# LPC18xx register map
File version: 0.23
CPU: CM3 r0p0, little endian, no MPU, no FPU, 3 interrupt priority bits
Registers are 32-bit, read-write, reset 0x0 unless marked. A register's access mark holds for its fields unless they carry their own. Offsets are from the block's base; [hi:lo] are bit positions; {n}, {i} and the like mark numbered series.

## TIMER0 — Timer0/1/2/3
Base 0x40084000
Same registers: TIMER1 0x40085000, TIMER2 0x400C3000, TIMER3 0x400C4000
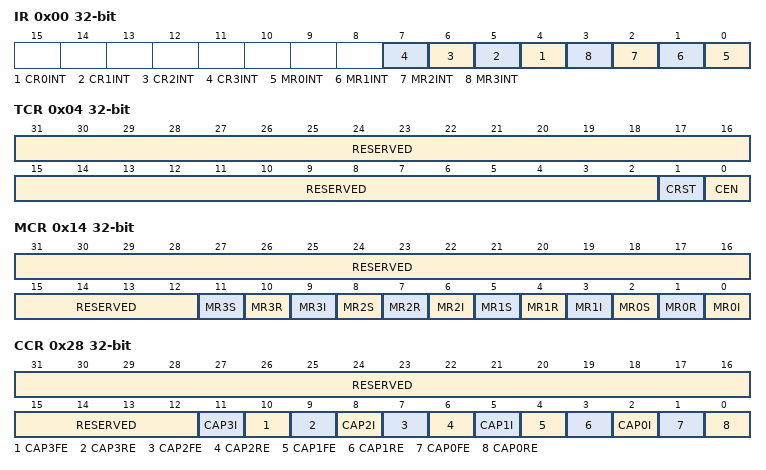
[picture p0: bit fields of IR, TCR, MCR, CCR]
0x00 IR — Interrupt Register. The IR can be written to clear interrupts. The IR can be read to identify which of eight possible interrupt sources are pending.
  [n+4] CR{n}INT (n=0..3) — Interrupt flag for capture channel {n} event.
  [n] MR{n}INT (n=0..3) — Interrupt flag for match channel {n}.
0x04 TCR — Timer Control Register. The TCR is used to control the Timer Counter functions. The Timer Counter can be disabled or reset through the TCR.
  [31:2] RESERVED — Reserved, user software should not write ones to reserved bits. The value read from a reserved bit is not defined.
  [1] CRST — When one, the Timer Counter and the Prescale Counter are synchronously reset on the next positive edge of PCLK. The counters remain reset until TCR[1] is returned to zero.
  [0] CEN — When one, the Timer Counter and Prescale Counter are enabled for counting. When zero, the counters are disabled.
0x08 TC — Timer Counter. The 32 bit TC is incremented every PR+1 cycles of PCLK. The TC is controlled through the TCR.
  [31:0] TC — Timer counter value.
0x0C PR — Prescale Register. When the Prescale Counter (PC) is equal to this value, the next clock increments the TC and clears the PC.
  [31:0] PM — Prescale counter maximum value.
0x10 PC — Prescale Counter. The 32 bit PC is a counter which is incremented to the value stored in PR. When the value in PR is reached, the TC is incremented and the PC is cleared. The PC is observable and controllable through the bus interface.
  [31:0] PC — Prescale counter value.
0x14 MCR — Match Control Register. The MCR is used to control if an interrupt is generated and if the TC is reset when a Match occurs.
  [31:12] RESERVED — Reserved, user software should not write ones to reserved bits. The value read from a reserved bit is not defined.
  [11] MR3S — Stop on MR3
    0=DISABLED (Disabled. Feature disabled.); 1=STOP (Stop. TC and PC will be stopped and TCR[0] will be set to 0 if MR3 matches the TC.)
  [10] MR3R — Reset on MR3
    0=DISABLED (Disabled. Feature disabled.); 1=MATCH (Match. TC will be reset if MR3 matches it.)
  [9] MR3I — Interrupt on MR3
    0=DISABLED (Disabled. This interrupt is disabled.); 1=INTERRUPT (Interrupt. Interrupt is generated when MR3 matches the value in the TC.)
  [8] MR2S — Stop on MR2.
    0=DISABLED (Disabled. Feature disabled.); 1=STOP (Stop. TC and PC will be stopped and TCR[0] will be set to 0 if MR2 matches the TC.)
  [7] MR2R — Reset on MR2
    0=DISABLED (Disabled. Feature disabled.); 1=MATCH (Match. TC will be reset if MR2 matches it.)
  [6] MR2I — Interrupt on MR2
    0=DISABLED (Disabled. Interrupt is disabled); 1=MATCH (Match. Interrupt is generated when MR2 matches the value in the TC.)
  [5] MR1S — Stop on MR1
    0=DISABLED (Disabled. Feature disabled.); 1=STOP (Stop. TC and PC will be stopped and TCR[0] will be set to 0 if MR1 matches the TC.)
  [4] MR1R — Reset on MR1
    0=DISABLED (Disabled. Feature disabled.); 1=RESET (Reset. TC will be reset if MR1 matches it.)
  [3] MR1I — Interrupt on MR1
    0=DISABLED (Disabled. Interrupt is disabled.); 1=MATCH (Match. Interrupt is generated when MR1 matches the value in the TC.)
  [2] MR0S — Stop on MR0
    0=DISABLED (Disabled. Feature disabled.); 1=MATCH (Match. TC and PC will be stopped and TCR[0] will be set to 0 if MR0 matches the TC.)
  [1] MR0R — Reset on MR0
    0=DISABLED (Disabled. Feature disabled.); 1=RESET (Reset. TC will be reset if MR0 matches it.)
  [0] MR0I — Interrupt on MR0
    0=DISABLED (Disabled. Interrupt is disabled); 1=ENABLED (Enabled. Interrupt is generated when MR0 matches the value in the TC.)
{0x18+4i} MR{i} (i=0..3) — Match Register 0. MR0 can be enabled through the MCR to reset the TC, stop both the TC and PC, and/or generate an interrupt every time MR0 matches the TC.
  [31:0] MATCH — Timer counter match value.
0x28 CCR — Capture Control Register. The CCR controls which edges of the capture inputs are used to load the Capture Registers and whether or not an interrupt is generated when a capture takes place.
  [31:12] RESERVED — Reserved, user software should not write ones to reserved bits. The value read from a reserved bit is not defined.
  [11] CAP3I — Interrupt on CAPn.3 event:
    0=DISABLED (Disabled. This feature is disabled.); 1=LOAD (Load. A CR3 load due to a CAPn.3 event will generate an interrupt.)
  [10] CAP3FE — High to low. Capture on CAPn.3 falling edge
    0=DISABLED (Disabled. This feature is disabled.); 1=HIGH_TO_LOW (A sequence of 1 then 0 on CAPn.3 will cause CR3 to be loaded with the contents of TC.)
  [9] CAP3RE — Capture on CAPn.3 rising edge
    0=DISABLED (Disabled. This feature is disabled.); 1=LOW_TO_HIGH (Low to high. A sequence of 0 then 1 on CAPn.3 will cause CR3 to be loaded with the contents of TC.)
  [8] CAP2I — Interrupt on CAPn.2 event
    0=DISABLED (Disabled. This feature is disabled.); 1=LOAD (Load. A CR2 load due to a CAPn.2 event will generate an interrupt.)
  [7] CAP2FE — Capture on CAPn.2 falling edge:
    0=DISABLED (Disabled. This feature is disabled.); 1=HIGH_TO_LOW (High to low. A sequence of 1 then 0 on CAPn.2 will cause CR2 to be loaded with the contents of TC.)
  [6] CAP2RE — Capture on CAPn.2 rising edge
    0=DISABLED (Disabled. This feature is disabled.); 1=LOW_TO_HIGH (Low to high. A sequence of 0 then 1 on CAPn.2 will cause CR2 to be loaded with the contents of TC.)
  [5] CAP1I — Interrupt on CAPn.1 event
    0=DISABLED (Disabled. This feature is disabled.); 1=LOAD (Load. A CR1 load due to a CAPn.1 event will generate an interrupt.)
  [4] CAP1FE — Capture on CAPn.1 falling edge
    0=DISABLED (Disabled. This feature is disabled.); 1=HIGH_TO_LOW (High to low. A sequence of 1 then 0 on CAPn.1 will cause CR1 to be loaded with the contents of TC.)
  [3] CAP1RE — Capture on CAPn.1 rising edge
    0=DISABLED (Disabled. This feature is disabled.); 1=LOW_TO_HIGH (Low to high. A sequence of 0 then 1 on CAPn.1 will cause CR1 to be loaded with the contents of TC.)
  [2] CAP0I — Interrupt on CAPn.0 event
    0=DISABLED (Disabled. This feature is disabled.); 1=LOAD (Load. A CR0 load due to a CAPn.0 event will generate an interrupt.)
  [1] CAP0FE — Capture on CAPn.0 falling edge
    0=DISABLED (Disabled. This feature is disabled.); 1=HIGH_TO_LOW (High to low. A sequence of 1 then 0 on CAPn.0 will cause CR0 to be loaded with the contents of TC.)
  [0] CAP0RE — Capture on CAPn.0 rising edge
    0=DISABLED (Disabled. This feature is disabled.); 1=LOW_TO_HIGH (Low to high. A sequence of 0 then 1 on CAPn.0 will cause CR0 to be loaded with the contents of TC.)
{0x2C+4i} CR{i} (i=0..3) ro — Capture Register 0. CR0 is loaded with the value of TC when there is an event on the CAPn.0 input.
  [31:0] CAP — Timer counter capture value.
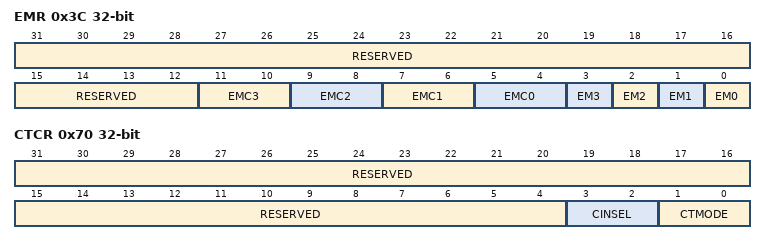
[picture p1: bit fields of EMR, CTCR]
0x3C EMR — External Match Register. The EMR controls the external match pins MATn.0-3 (MAT0.0-3 and MAT1.0-3 respectively).
  [31:12] RESERVED — Reserved, user software should not write ones to reserved bits. The value read from a reserved bit is not defined.
  [2n+5:2n+4] EMC{n} (n=0..3) — External Match Control {n}. Determines the functionality of External Match {n}.
    0=NOP (Do Nothing.); 1=CLEAR (Clear. Clear the corresponding External Match bit/output to 0 (MATn.m pin is LOW if pinned out).); 2=SET (Set. Set the corresponding External Match bit/output to 1 (MATn.m pin is HIGH if pinned out).); 3=TOGGLE (Toggle. Toggle the corresponding External Match bit/output.)
  [3] EM3 — External Match 3. When a match occurs between the TC and MR3, this bit can either toggle, go low, go high, or do nothing, depending on bits 11:10 of this register. This bit can be driven onto a MATn.0 pin, in a positive-logic manner (0 = low, 1 = high).
  [2] EM2 — External Match 2. When a match occurs between the TC and MR2, this bit can either toggle, go low, go high, or do nothing, depending on bits 9:8 of this register. This bit can be driven onto a MATn.0 pin, in a positive-logic manner (0 = low, 1 = high).
  [1] EM1 — External Match 1. When a match occurs between the TC and MR1, this bit can either toggle, go low, go high, or do nothing, depending on bits 7:6 of this register. This bit can be driven onto a MATn.1 pin, in a positive-logic manner (0 = low, 1 = high).
  [0] EM0 — External Match 0. When a match occurs between the TC and MR0, this bit can either toggle, go low, go high, or do nothing, depending on bits 5:4 of this register. This bit can be driven onto a MATn.0 pin, in a positive-logic manner (0 = low, 1 = high).
0x70 CTCR — Count Control Register. The CTCR selects between Timer and Counter mode, and in Counter mode selects the signal and edge(s) for counting.
  [31:4] RESERVED — Reserved, user software should not write ones to reserved bits. The value read from a reserved bit is not defined.
  [3:2] CINSEL — Count Input Select When bits 1:0 in this register are not 00, these bits select which CAP pin is sampled for clocking. Note: If Counter mode is selected for a particular CAPn input in the TnCTCR, the 3 bits for that input in the Capture Control Register (TnCCR) must be programmed as 000. However, capture and/or interrupt can be selected for the other 3 CAPn inputs in the same timer.
    0=CAP0 (CAP0. CAPn.0 for TIMERn); 1=CAP1 (CAP1. CAPn.1 for TIMERn); 2=CAP2 (CAP2. CAPn.2 for TIMERn); 3=CAP3 (CAP3. CAPn.3 for TIMERn)
  [1:0] CTMODE — Counter/Timer Mode This field selects which rising PCLK edges can increment Timer's Prescale Counter (PC), or clear PC and increment Timer Counter (TC). Timer Mode: the TC is incremented when the Prescale Counter matches the Prescale Register.
    0=TIMER_MODE (Timer Mode. Counts every rising PCLK edge); 1=COUNTER_MODE_RISING (Counter Mode rising edge. TC is incremented on rising edges on the CAP input selected by bits 3:2.); 2=COUNTER_MODE_FALLING (Counter Mode falling edge. TC is incremented on falling edges on the CAP input selected by bits 3:2.); 3=COUNTER_MODE_EDGES (Counter Mode edges. TC is incremented on both edges on the CAP input selected by bits 3:2.)
